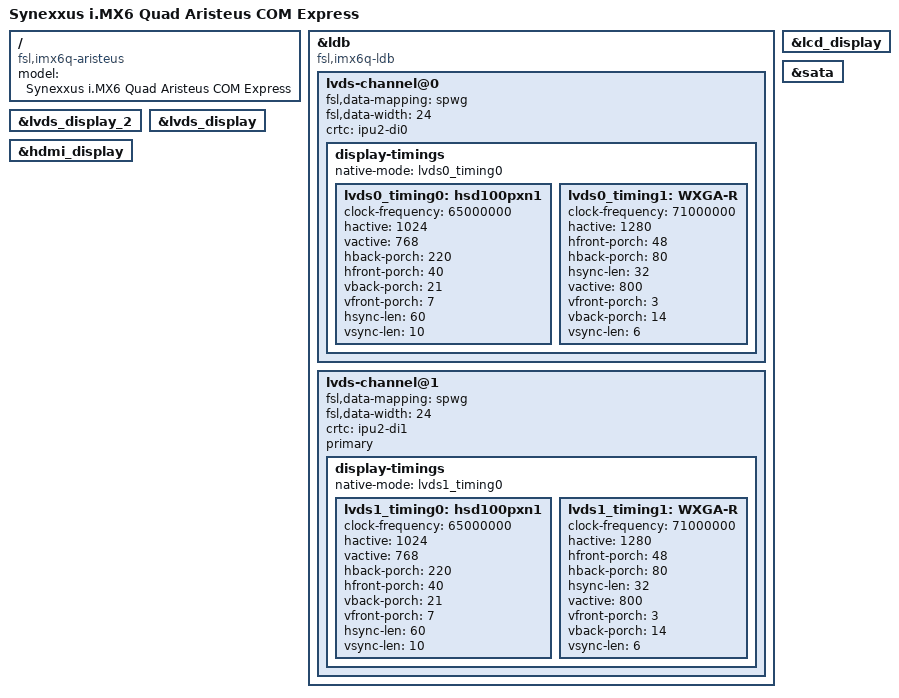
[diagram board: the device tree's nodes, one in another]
/*
 * Copyright 2014 Synexxus, Inc.
 * Copyright 2012 Freescale Semiconductor, Inc.
 * Copyright 2011 Linaro Ltd.
 *
 * The code contained herein is licensed under the GNU General Public
 * License. You may obtain a copy of the GNU General Public License
 * Version 2 or later at the following locations:
 *
 * http://www.opensource.org/licenses/gpl-license.html
 * http://www.gnu.org/copyleft/gpl.html
 *
 * Update: 12/16/2014
 * Time: 10AM
 */

/dts-v1/;

//#include <dt-bindings/interrupt-controller/irq.h>
#include "imx6q.dtsi"
#include "imx6qdl-aristeus.dtsi"

/ {
	model = "Synexxus i.MX6 Quad Aristeus COM Express";
	compatible = "fsl,imx6q-aristeus", "fsl,imx6q";
};

&ldb {
	compatible = "fsl,imx6q-ldb";
	status = "okay";

	lvds-channel@0 {
		fsl,data-mapping = "spwg";
		fsl,data-width = <24>;
		crtc = "ipu2-di0";
		status = "okay";

		display-timings {
			native-mode = <&lvds0_timing0>;
			lvds0_timing0: hsd100pxn1 {
				clock-frequency = <65000000>;
				hactive = <1024>;
				vactive = <768>;
				hback-porch = <220>;
				hfront-porch = <40>;
				vback-porch = <21>;
				vfront-porch = <7>;
				hsync-len = <60>;
				vsync-len = <10>;
			};
			lvds0_timing1: WXGA-R {
				clock-frequency = <71000000>;
				hactive = <1280>;
				hfront-porch = <48>;
				hback-porch = <80>;
				hsync-len = <32>;
				vactive = <800>;
				vfront-porch = <3>;
				vback-porch = <14>;
				vsync-len = <6>;
			};
		};
	};

	lvds-channel@1 {
		fsl,data-mapping = "spwg";
		fsl,data-width = <24>;
		crtc = "ipu2-di1";
		status = "okay";
		primary;

		display-timings {
			native-mode = <&lvds1_timing0>;
			lvds1_timing0: hsd100pxn1 {
				clock-frequency = <65000000>;
				hactive = <1024>;
				vactive = <768>;
				hback-porch = <220>;
				hfront-porch = <40>;
				vback-porch = <21>;
				vfront-porch = <7>;
				hsync-len = <60>;
				vsync-len = <10>;
			};
			lvds1_timing1: WXGA-R {
				clock-frequency = <71000000>;
				hactive = <1280>;
				hfront-porch = <48>;
				hback-porch = <80>;
				hsync-len = <32>;
				vactive = <800>;
				vfront-porch = <3>;
				vback-porch = <14>;
				vsync-len = <6>;
			};
		};
	};
};

&lvds_display_2 {
	status = "okay";
};

&lvds_display {
	status = "okay";
};

&hdmi_display {
	status = "okay";
};

&lcd_display {
	status = "okay";
};

&sata {
	status = "okay";
};


